# CC3200 register map
Vendor: Texas Instruments; Series: SimpleLink; File version: 1.0
CPU: CM4 r0p1, little endian, MPU, no FPU, 3 interrupt priority bits
Registers are 32-bit, read-write, reset 0x0 unless marked. A register's access mark holds for its fields unless they carry their own. Offsets are from the block's base; [hi:lo] are bit positions.

## CAMERA
Base 0x44018000
0x00 CC_REVISION — CAMERA_CC_REVISION
  [7:0] REV_M
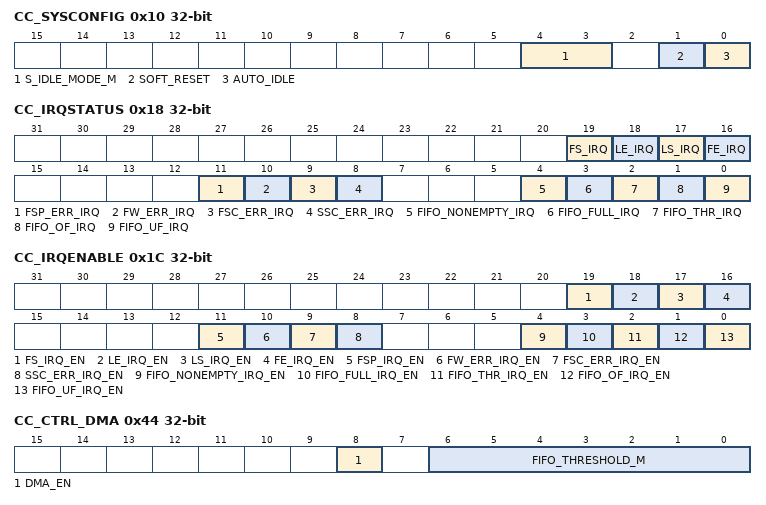
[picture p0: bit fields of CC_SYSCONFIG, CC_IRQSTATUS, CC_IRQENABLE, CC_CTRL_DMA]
0x10 CC_SYSCONFIG — CAMERA_CC_SYSCONFIG
  [4:3] S_IDLE_MODE_M — CAMERA_CC_SYSCONFIG
  [1] SOFT_RESET — CAMERA_CC_SYSCONFIG
  [0] AUTO_IDLE — CAMERA_CC_SYSCONFIG
0x14 CC_SYSSTATUS — CAMERA_CC_SYSSTATUS
  [0] RESET_DONE2
0x18 CC_IRQSTATUS — CAMERA_CC_IRQSTATUS
  [19] FS_IRQ — CAMERA_CC_IRQSTATUS
  [18] LE_IRQ — CAMERA_CC_IRQSTATUS
  [17] LS_IRQ — CAMERA_CC_IRQSTATUS
  [16] FE_IRQ — CAMERA_CC_IRQSTATUS
  [11] FSP_ERR_IRQ — CAMERA_CC_IRQSTATUS
  [10] FW_ERR_IRQ — CAMERA_CC_IRQSTATUS
  [9] FSC_ERR_IRQ — CAMERA_CC_IRQSTATUS
  [8] SSC_ERR_IRQ — CAMERA_CC_IRQSTATUS
  [4] FIFO_NONEMPTY_IRQ — CAMERA_CC_IRQSTATUS
  [3] FIFO_FULL_IRQ — CAMERA_CC_IRQSTATUS
  [2] FIFO_THR_IRQ — CAMERA_CC_IRQSTATUS
  [1] FIFO_OF_IRQ — CAMERA_CC_IRQSTATUS
  [0] FIFO_UF_IRQ — CAMERA_CC_IRQSTATUS
0x1C CC_IRQENABLE — CAMERA_CC_IRQENABLE
  [19] FS_IRQ_EN — CAMERA_CC_IRQENABLE
  [18] LE_IRQ_EN — CAMERA_CC_IRQENABLE
  [17] LS_IRQ_EN — CAMERA_CC_IRQENABLE
  [16] FE_IRQ_EN — CAMERA_CC_IRQENABLE
  [11] FSP_IRQ_EN — CAMERA_CC_IRQENABLE
  [10] FW_ERR_IRQ_EN — CAMERA_CC_IRQENABLE
  [9] FSC_ERR_IRQ_EN — CAMERA_CC_IRQENABLE
  [8] SSC_ERR_IRQ_EN — CAMERA_CC_IRQENABLE
  [4] FIFO_NONEMPTY_IRQ_EN — CAMERA_CC_IRQENABLE
  [3] FIFO_FULL_IRQ_EN — CAMERA_CC_IRQENABLE
  [2] FIFO_THR_IRQ_EN — CAMERA_CC_IRQENABLE
  [1] FIFO_OF_IRQ_EN — CAMERA_CC_IRQENABLE
  [0] FIFO_UF_IRQ_EN — CAMERA_CC_IRQENABLE
0x40 CC_CTRL — CAMERA_CC_CTRL
  [19] CC_IF_SYNCHRO — CAMERA_CC_CTRL
  [18] CC_RST — CAMERA_CC_CTRL
  [17] CC_FRAME_TRIG — CAMERA_CC_CTRL
  [16] CC_EN — CAMERA_CC_CTRL
  [13] NOBT_SYNCHRO — CAMERA_CC_CTRL
  [12] BT_CORRECT — CAMERA_CC_CTRL
  [11] PAR_ORDERCAM — CAMERA_CC_CTRL
  [10] PAR_CLK_POL — CAMERA_CC_CTRL
  [9] NOBT_HS_POL — CAMERA_CC_CTRL
  [8] DMA_DMA_EN — CAMERA_CC_CTRL
  [8] NOBT_VS_POL — CAMERA_CC_CTRL
  [3:1] PAR_MODE_M — CAMERA_CC_CTRL
  [0] CCP_MODE — CAMERA_CC_CTRL
  [6:0] DMA_FIFO_THRESHOLD_M — CAMERA_CC_CTRL
  [4:0] XCLK_XCLK_DIV_M — CAMERA_CC_CTRL
0x44 CC_CTRL_DMA — CAMERA_CC_CTRL_DMA
  [8] DMA_EN — CAMERA_CC_CTRL_DMA
  [6:0] FIFO_THRESHOLD_M — CAMERA_CC_CTRL_DMA
0x48 CC_CTRL_XCLK — CAMERA_CC_CTRL_XCLK
  [4:0] XCLK_DIV_M
0x4C CC_FIFO_DATA — CAMERA_CC_FIFO_DATA
  [31:0] FIFO_DATA_M
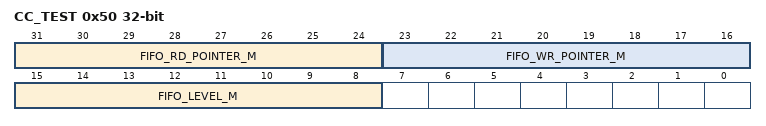
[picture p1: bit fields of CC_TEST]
0x50 CC_TEST — CAMERA_CC_TEST
  [31:24] FIFO_RD_POINTER_M — CAMERA_CC_TEST
  [23:16] FIFO_WR_POINTER_M — CAMERA_CC_TEST
  [15:8] FIFO_LEVEL_M — CAMERA_CC_TEST
0x54 CC_GEN_PAR — CAMERA_CC_GEN_PAR
  [2:0] CC_FIFO_DEPTH_M

## DES
Base 0x44039000
0x00 KEY3_L — DES_KEY3_L
  [31:0] KEY3_L_M
0x04 KEY3_H — DES_KEY3_H
  [31:0] KEY3_H_M
0x08 KEY2_L — DES_KEY2_L
  [31:0] KEY2_L_M
0x0C KEY2_H — DES_KEY2_H
  [31:0] KEY2_H_M
0x10 KEY1_L — DES_KEY1_L
  [31:0] KEY1_L_M
0x14 KEY1_H — DES_KEY1_H
  [31:0] KEY1_H_M
0x18 IV_L — DES_IV_L
  [31:0] IV_L_M
0x1C IV_H — DES_IV_H
  [31:0] IV_H_M
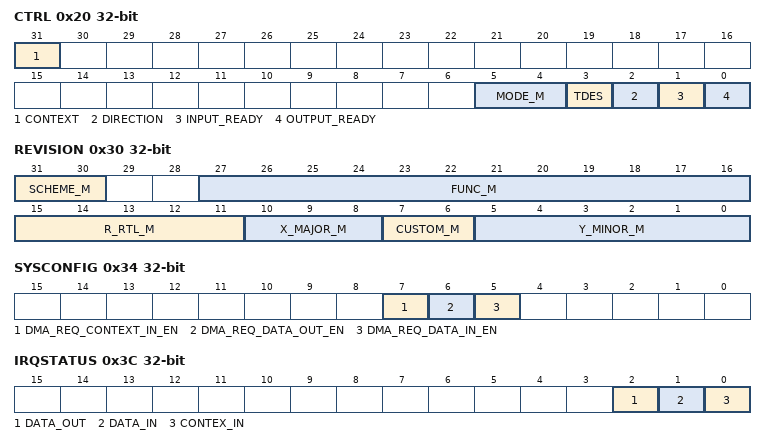
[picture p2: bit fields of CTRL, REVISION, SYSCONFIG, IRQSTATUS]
0x20 CTRL — DES_CTRL
  [31] CONTEXT — DES_CTRL
  [5:4] MODE_M — DES_CTRL
  [3] TDES — DES_CTRL
  [2] DIRECTION — DES_CTRL
  [1] INPUT_READY — DES_CTRL
  [0] OUTPUT_READY — DES_CTRL
0x24 LENGTH — DES_LENGTH
  [31:0] LENGTH_M
0x28 DATA_L — DES_DATA_L
  [31:0] DATA_L_M
0x2C DATA_H — DES_DATA_H
  [31:0] DATA_H_M
0x30 REVISION — DES_REVISION
  [31:30] SCHEME_M — DES_REVISION
  [27:16] FUNC_M — DES_REVISION
  [15:11] R_RTL_M — DES_REVISION
  [10:8] X_MAJOR_M — DES_REVISION
  [7:6] CUSTOM_M — DES_REVISION
  [5:0] Y_MINOR_M — DES_REVISION
0x34 SYSCONFIG — DES_SYSCONFIG
  [7] DMA_REQ_CONTEXT_IN_EN — DES_SYSCONFIG
  [6] DMA_REQ_DATA_OUT_EN — DES_SYSCONFIG
  [5] DMA_REQ_DATA_IN_EN — DES_SYSCONFIG
0x38 SYSSTATUS — DES_SYSSTATUS
  [0] RESETDONE
0x3C IRQSTATUS — DES_IRQSTATUS
  [2] DATA_OUT — DES_IRQSTATUS
  [1] DATA_IN — DES_IRQSTATUS
  [0] CONTEX_IN — DES_IRQSTATUS
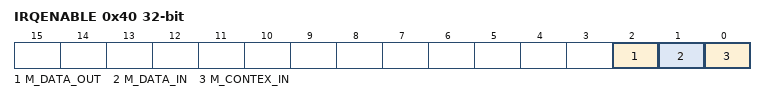
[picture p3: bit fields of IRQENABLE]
0x40 IRQENABLE — DES_IRQENABLE
  [2] M_DATA_OUT — DES_IRQENABLE
  [1] M_DATA_IN — DES_IRQENABLE
  [0] M_CONTEX_IN — DES_IRQENABLE
